# SN32F260 register map
Vendor: SONiX Technology Co., Ltd.; Series: SN32F260; File version: 1.1
CPU: CM0 r0p0, little endian, no MPU, no FPU, 2 interrupt priority bits
Registers are 32-bit, read-write, reset 0x0 unless marked. A register's access mark holds for its fields unless they carry their own. Offsets are from the block's base; [hi:lo] are bit positions; {n}, {i} and the like mark numbered series.

## SN_SYS1 — System Control Registers
Base 0x4005E000
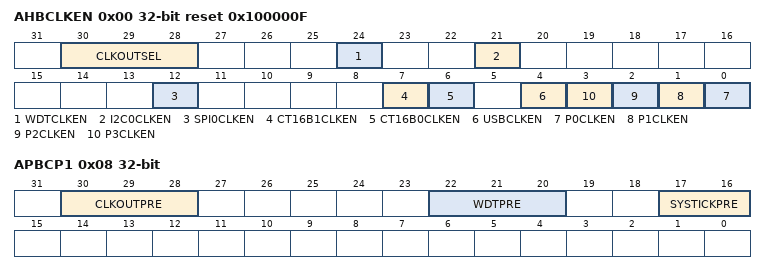
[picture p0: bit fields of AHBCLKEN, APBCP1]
0x00 AHBCLKEN reset 0x100000F — Offset:0x00 AHB Clock Enable Register
  [30:28] CLKOUTSEL — Clock output source selection
    0=Disable; 1=ILRC; 4=HCLK; 5=IHRC
  [24] WDTCLKEN — Enable AHB clock for WDT
    0=Disable; 1=Enable
  [21] I2C0CLKEN — Enable AHB clock for I2C0
    0=Disable; 1=Enable
  [12] SPI0CLKEN — Enable AHB clock for SPI0
    0=Disable; 1=Enable
  [7] CT16B1CLKEN — Enable AHB clock for CT16B1
    0=Disable; 1=Enable
  [6] CT16B0CLKEN — Enable AHB clock for CT16B0
    0=Disable; 1=Enable
  [4] USBCLKEN — Enable AHB clock for USB
    0=Disable; 1=Enable
  [n] P{n}CLKEN (n=0..3) — Enable AHB clock for P{n}
    0=Disable; 1=Enable
0x08 APBCP1 — Offset:0x08 APB Clock Prescale Register 1
  [30:28] CLKOUTPRE — CLKOUT APB clock source prescaler
    0=FCLKOUT/1; 1=FCLKOUT/2; 2=FCLKOUT/4; 3=FCLKOUT/8; 4=FCLKOUT/16; 5=FCLKOUT/32; 6=FCLKOUT/64; 7=FCLKOUT/128
  [22:20] WDTPRE — WDT APB clock source prescaler
    0=HCLK/1; 1=HCLK/2; 2=HCLK/4; 3=HCLK/8; 4=HCLK/16; 5=HCLK/32
  [17:16] SYSTICKPRE — SysTick APB clock source prescaler
    0=HCLK/1; 1=HCLK/2; 2=HCLK/4; 3=HCLK/8

## SN_WDT — Watchdog Timer
Base 0x40010000
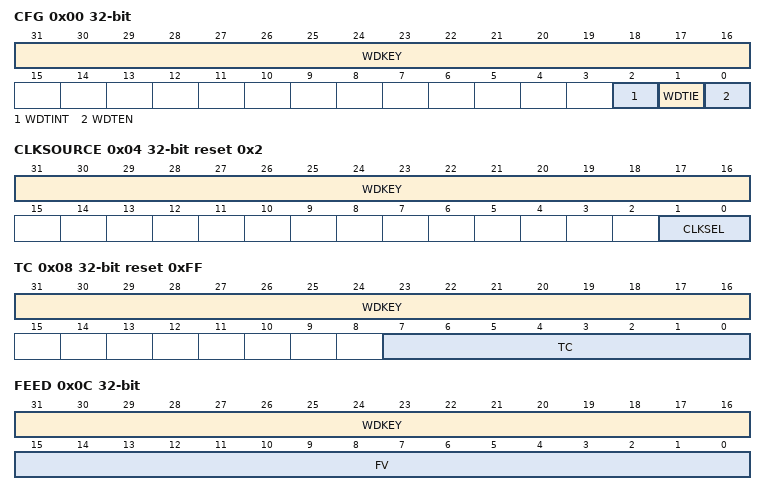
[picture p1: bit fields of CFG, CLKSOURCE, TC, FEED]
0x00 CFG — Offset:0x00 WDT Configuration Register
  [31:16] WDKEY wo — WDT register key
  [2] WDTINT — WDT interrupt flag
    0=No (No WDT time-out); 1=WDT time-out (WDT interrupt is triggered if WDTIE=1)
  [1] WDTIE — WDT interrupt enable
    0=Disable (WDT reset when WDT time-out); 1=Enable WDT interrupt
  [0] WDTEN — WDT enable
    0=Disable WDT; 1=Enable WDT
0x04 CLKSOURCE reset 0x2 — Offset:0x04 WDT Clock Source Register
  [31:16] WDKEY wo — WDT register key
  [1:0] CLKSEL — WDT clock source
    2=ILRC (WDT clock source=ILRC)
0x08 TC reset 0xFF — Offset:0x08 WDT Timer Constant Register
  [31:16] WDKEY wo — WDT register key
  [7:0] TC — Watchdog timer constant reload value
0x0C FEED wo — Offset:0x0C WDT Feed Register
  [31:16] WDKEY — WDT register key
  [15:0] FV — Watchdog feed value

## SN_CT16B0 — 16-bit Timer 0 with Capture function
Base 0x40000000
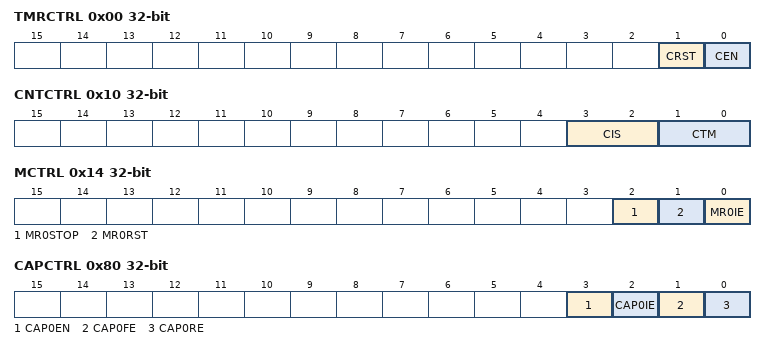
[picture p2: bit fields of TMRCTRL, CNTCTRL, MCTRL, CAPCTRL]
0x00 TMRCTRL — Offset:0x00 CT16Bn Timer Control Register
  [1] CRST — Counter Reset
    0=Disable; 1=Reset Counter (Timer Counter and the Prescale Counter are synchronously reset on the next positive edge of PCLK)
  [0] CEN — Counter enable
    0=Disable counter; 1=Enable Timer Counter and Prescale Counter for counting
0x04 TC — Offset:0x04 CT16Bn Timer Counter Register
  [15:0] TC — Timer Counter
0x08 PRE — Offset:0x08 CT16Bn Prescale Register
  [7:0] PRE — Prescaler
0x0C PC — Offset:0x0C CT16Bn Prescale Counter Register
  [7:0] PC — Prescaler Counter
0x10 CNTCTRL — Offset:0x10 CT16Bn Counter Control Register
  [3:2] CIS — Counter Input Select
    0=CT16Bn_CAP0
  [1:0] CTM — Counter/Timer Mode
    0=Timer Mode (Every rising PCLK edge); 1=Counter Mode Rising (TC is incremented on rising edges on the CAP0 input selected by CIS bits.); 2=Counter Mode Falling (TC is incremented on falling edges on the CAP0 input selected by CIS bits.); 3=Counter Mode (TC is incremented on both edges on the CAP0 input selected by CIS bits.)
0x14 MCTRL — Offset:0x14 CT16Bn Match Control Register
  [2] MR0STOP — Stop TC and PC and clear CEN bit when MR0 matches TC
    0=Disable; 1=Enable (Stop TC and PC and clear CEN bit when MR0 matches TC)
  [1] MR0RST — Enable reset TC when MR0 matches TC
    0=Disable; 1=Enable (Reset TC when MR0 matches TC)
  [0] MR0IE — Enable generating an interrupt when MR0 matches TC
    0=Disable; 1=Enable (Generating an interrupt when MR0 matches TC)
0x20 MR0 (reset mask 0xFFFF) — Offset:0x20 CT16Bn MR0 Register
0x80 CAPCTRL — Offset:0x80 CT16Bn Capture Control Register
  [3] CAP0EN — CAP0 function enable
    0=Disable; 1=Enable CAP0 function
  [2] CAP0IE — Interrupt on CT16Bn_CAP0 event
    0=Disable; 1=Enable (A CAP0 load due to a CT16Bn_CAP0 event will generate an interrupt.)
  [1] CAP0FE — Capture on CT16Bn_CAP0 falling edge
    0=Disable; 1=Enable (A sequence of 1 then 0 on CT16Bn_CAP0 will cause CAP0 to be loaded with the contents of TC.)
  [0] CAP0RE — Capture on CT16Bn_CAP0 rising edge
    0=Disable; 1=Enable (A sequence of 0 then 1 on CT16Bn_CAP0 will cause CAP0 to be loaded with the contents of TC.)
0x84 CAP0 ro — Offset:0x84 CT16Bn CAP0 Register
  [15:0] CAP0 — Timer counter capture value
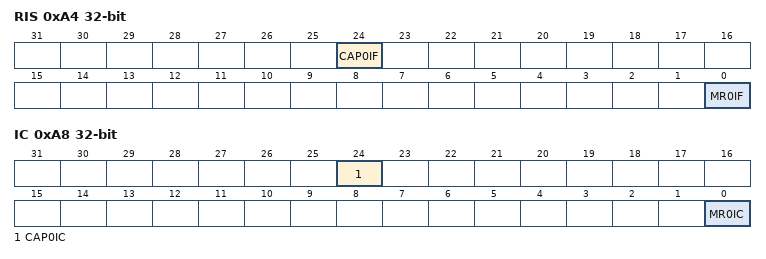
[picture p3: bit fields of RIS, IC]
0xA4 RIS ro — Offset:0xA4 CT16Bn Raw Interrupt Status Register
  [24] CAP0IF — Capture channel 0 interrupt flag
    0=No (No interrupt on CAP0); 1=Met interrupt requirements (Interrupt requirements met on CAP0)
  [0] MR0IF — Match channel 0 interrupt flag
    0=No interrupt on match channel 0; 1=Met interrupt requirements (Interrupt requirements met on match channel 0)
0xA8 IC wo — Offset:0xA8 CT16Bn Interrupt Clear Register
  [24] CAP0IC — CAP0IF clear bit
    0=No effect; 1=Clear CAP0IF
  [0] MR0IC — MR0IF clear bit
    0=No effect; 1=Clear MR0IF
